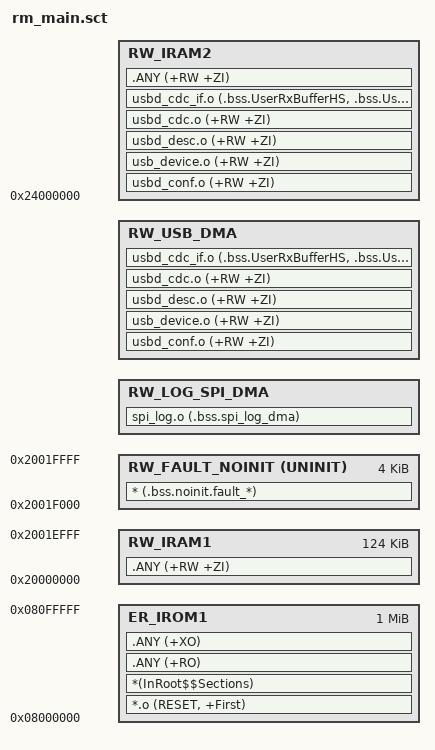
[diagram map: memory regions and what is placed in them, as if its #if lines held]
#! armclang -E --target=arm-arm-none-eabi -mcpu=cortex-m7 -xc
#include "D:/RM/wheel_leg_2026/wheel_leg_2025--4/rm_main/User/Log/fault_log_config.h"
#include "D:/RM/wheel_leg_2026/wheel_leg_2025--4/rm_main/User/Log/spi_log_config.h"
#include "D:/RM/wheel_leg_2026/wheel_leg_2025--4/rm_main/User/Support/usb_dma_memory.h"
/* H723：保留故障现场，并为 SPI DMA 分配独立的 AXI SRAM。 */
LR_IROM1 0x08000000 0x00100000 {
  ER_IROM1 0x08000000 0x00100000 {
    *.o (RESET, +First)
    *(InRoot$$Sections)
    .ANY (+RO)
    .ANY (+XO)
  }
  RW_IRAM1 0x20000000 0x0001F000 {
    .ANY (+RW +ZI)
  }
#if FAULT_LOG_TEST_IRAM1
  RW_FAULT_NOINIT 0x2001F000 UNINIT 0x00001000 {
#else
  RW_FAULT_NOINIT 0x2404F000 UNINIT 0x00001000 {
#endif
    * (.bss.noinit.fault_*)
  }
  RW_LOG_SPI_DMA LOG_SPI_DMA_BASE LOG_SPI_DMA_BYTES {
    spi_log.o (.bss.spi_log_dma)
  }
#if USB_DMA_PROTECTED_REQUIRED
  /* SPI 日志与其他 USB DMA 业务并存时，USB 使用独立非缓存区。 */
  RW_USB_DMA USB_DMA_REGION_BASE USB_DMA_REGION_BYTES {
    usbd_conf.o (+RW +ZI)
    usb_device.o (+RW +ZI)
    usbd_desc.o (+RW +ZI)
    usbd_cdc.o (+RW +ZI)
    usbd_cdc_if.o (.bss.UserRxBufferHS, .bss.UserTxBufferHS)
  }
  RW_IRAM2 0x24000000 (USB_DMA_REGION_BASE - 0x24000000) {
#else
  RW_IRAM2 0x24000000 (LOG_SPI_DMA_BASE - 0x24000000) {
#endif
#if DMA_MEMORY_USB_DMA_ENABLED && !USB_DMA_PROTECTED_REQUIRED
    /* 无须非缓存 MPU 区时仍将 USB DMA 数据明确放入 AXI SRAM。 */
    usbd_conf.o (+RW +ZI)
    usb_device.o (+RW +ZI)
    usbd_desc.o (+RW +ZI)
    usbd_cdc.o (+RW +ZI)
    usbd_cdc_if.o (.bss.UserRxBufferHS, .bss.UserTxBufferHS)
#endif
    .ANY (+RW +ZI)
  }
}
